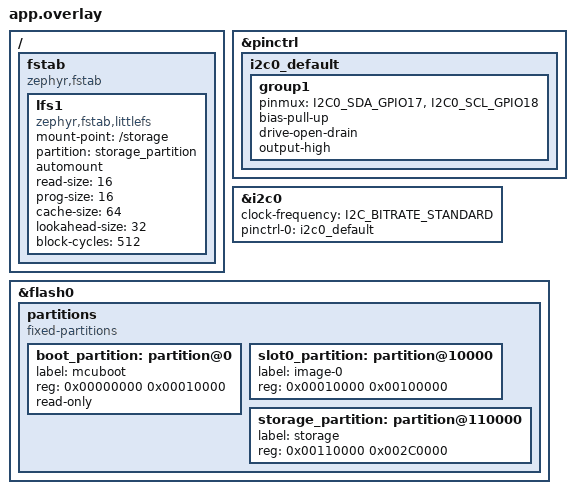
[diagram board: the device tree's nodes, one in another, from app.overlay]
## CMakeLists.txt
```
cmake_minimum_required(VERSION 3.20.0)
find_package(Zephyr REQUIRED HINTS $ENV{ZEPHYR_BASE})
project(meu_lora)

# Inclui o diretório de cabeçalhos
target_include_directories(app PRIVATE
    include
)

# # Subdiretórios
# add_subdirectory(src/federatedfearning)
# add_subdirectory(src/http)
# add_subdirectory(src/CJSON)
# add_subdirectory(src/websocket)

# add_subdirectory(src/espconfiguration)

# Adiciona os arquivos fonte do projeto
target_sources(app PRIVATE 
    src/main.c 
    # src/cJSON.c
    src/espconfiguration.c
    src/federatedlearning.c
    src/httpclient.c
    src/JSONConverter.c
    src/websocketclient.c
    src/knowledgedistillation.c
)
```

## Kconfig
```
mainmenu "Federated Learning node"

menu "Federated learning"

config FL_KNOWLEDGE_DISTILLATION
	bool "Knowledge distillation from a server-provided teacher"
	default n
	help
	  Distills a teacher model, downloaded from /api/getteachermodel at every round,
	  into the local model during training. Can also be changed at runtime with
	  KnowledgeDistillationEnable()/KnowledgeDistillationDisable().

config FL_KD_TEMPERATURE_X10
	int "Default distillation temperature x10 (30 = 3.0)"
	default 30
	range 10 200
	help
	  Used when the server does not send "distillation.temperature" with the teacher.

config FL_KD_ALPHA_PERCENT
	int "Default distillation weight alpha in percent"
	default 50
	range 0 100
	help
	  Weight of the distillation term; 0 is plain cross-entropy training.
	  Used when the server does not send "distillation.alpha" with the teacher.

endmenu

source "Kconfig.zephyr"
```

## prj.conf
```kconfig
# LORA
# CONFIG_LORA=y
# CONFIG_MAIN_STACK_SIZE=2048
# CONFIG_SYSTEM_WORKQUEUE_STACK_SIZE=2048

# LOG
CONFIG_LOG=y
CONFIG_LOG_DEFAULT_LEVEL=3

# pra usar printf
CONFIG_NEWLIB_LIBC=y
CONFIG_STDOUT_CONSOLE=y
CONFIG_PRINTK=y

# Wi-Fi Configuration
CONFIG_WIFI=y

CONFIG_WIFI_ESP32=y
CONFIG_WIFI_LOG_LEVEL_INF=y


# Network Configuration
CONFIG_NET_CONFIG_AUTO_INIT=n
CONFIG_NET_CONNECTION_MANAGER=y
CONFIG_NET_DHCPV4=y
CONFIG_NET_IF_MAX_IPV4_COUNT=2
CONFIG_NET_IPV4=y
CONFIG_NET_L2_ETHERNET=y
CONFIG_NET_L2_WIFI_MGMT=y
CONFIG_NET_MGMT=y
CONFIG_NET_MGMT_EVENT=y
CONFIG_NET_MGMT_EVENT_INFO=y
CONFIG_NET_MGMT_EVENT_QUEUE_SIZE=10
CONFIG_NET_MGMT_EVENT_STACK_SIZE=4096
CONFIG_NET_PKT_RX_COUNT=16
CONFIG_NET_PKT_TX_COUNT=16
CONFIG_NET_SOCKETS_SERVICE_STACK_SIZE=4096
CONFIG_NET_TCP=y
CONFIG_NET_UDP=y
CONFIG_NETWORKING=y

CONFIG_NET_MAX_CONN=20
CONFIG_NET_MAX_CONTEXTS=20

# LOG Configuration
CONFIG_NET_LOG=y
CONFIG_NET_DHCPV4_SERVER_LOG_LEVEL_DBG=y



# --- Rede básica ---
CONFIG_NET_IPV6=n
CONFIG_NET_SOCKETS=y


# --- Gerenciamento de rede ---
CONFIG_NET_MGMT=y
CONFIG_NET_MGMT_EVENT=y
CONFIG_NET_MGMT_EVENT_THREAD=y

# --- WebSocket & HTTP ---
CONFIG_HTTP_CLIENT=y
CONFIG_WEBSOCKET_CLIENT=y


# --- Gerenciamento de Memória e Stack ---
# Heap do kernel (k_malloc): usado pelo driver Wi-Fi (CONFIG_ESP_WIFI_HEAP_SYSTEM) e pelo kernel.
# A rede neural e o cJSON NÃO usam esse heap: usam malloc/calloc da newlib, cuja arena é a DRAM que
# sobra entre _end e _heap_sentry. Cada byte a mais aqui sai dessa arena -- com 96KB a arena caía
# para ~139KB e o nó ficava sem memória para enviar/receber o modelo depois de cachear o teacher.
CONFIG_HEAP_MEM_POOL_SIZE=65536

# Aumenta a pilha da thread principal para lidar com a recursividade do cJSON e buffers de rede
CONFIG_MAIN_STACK_SIZE=8192

# --- Sistema de Arquivos (LittleFS) ---
CONFIG_FILE_SYSTEM=y
CONFIG_FILE_SYSTEM_LITTLEFS=y
CONFIG_FLASH=y
CONFIG_FLASH_MAP=y
CONFIG_FLASH_PAGE_LAYOUT=y

# # --- Sensores e Barramentos ---
# CONFIG_I2C=y

# --- Suporte a Ponto Flutuante (Floats) nos Logs ---
CONFIG_CBPRINTF_FP_SUPPORT=y

#===aaa
# # --- Suporte a GPIO ---
# CONFIG_GPIO=y

# --- Suporte Avançado de Wi-Fi ---
CONFIG_WIFI=y
CONFIG_NET_L2_WIFI_MGMT=y
CONFIG_WIFI_LOG_LEVEL_INF=y

# Degub
# CONFIG_WIFI_LOG_LEVEL_ERR=y
# CONFIG_NET_DHCPV4_LOG_LEVEL_DBG=y
# CONFIG_NET_IPV4_LOG_LEVEL_DBG=y

CONFIG_CJSON=y

# Habilita a Biblioteca C completa com suporte a arquivos
CONFIG_NEWLIB_LIBC=y

# Liga a ponte entre o fopen() do C e o Virtual File System do Zephyr
CONFIG_POSIX_API=y
CONFIG_POSIX_FILE_SYSTEM=y

# config de flash e particionamento
CONFIG_FLASH=y
CONFIG_FLASH_MAP=y

CONFIG_FILE_SYSTEM=y
CONFIG_FILE_SYSTEM_LITTLEFS=y

# --- Knowledge distillation (teacher enviado pelo servidor em /api/getteachermodel) ---
CONFIG_FL_KNOWLEDGE_DISTILLATION=n
# Valores padrão usados se o servidor não enviar "distillation" junto com o teacher
CONFIG_FL_KD_TEMPERATURE_X10=30
CONFIG_FL_KD_ALPHA_PERCENT=50
```

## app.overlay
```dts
/* Importa o dicionário de pinos do ESP32-S3 */
#include <zephyr/dt-bindings/pinctrl/esp32s3-pinctrl.h>

/* Importa o dicionário de velocidades do I2C (Resolve o erro do BITRATE) */
#include <zephyr/dt-bindings/i2c/i2c.h>

/ {
	/* 1. Configuração de Automount do Sistema de Arquivos */
	fstab {
		compatible = "zephyr,fstab";
		lfs1: lfs1 {
			compatible = "zephyr,fstab,littlefs";
			mount-point = "/storage";
			partition = <&storage_partition>;
			automount;
			read-size = <16>;
			prog-size = <16>;
			cache-size = <64>;
			lookahead-size = <32>;
			block-cycles = <512>;
		};
	};
};

/* 2. Mapeamento dos Pinos para o ESP32-S3 (Heltec V3) */
&pinctrl {
	i2c0_default: i2c0_default {
		group1 {
			/* Pinos I2C ajustados para o hardware da Heltec V3 */
			/* Se o seu sensor estiver em pinos diferentes, mude os números abaixo (ex: GPIO41) */
			pinmux = <I2C0_SDA_GPIO17>, <I2C0_SCL_GPIO18>;
			bias-pull-up;
			drive-open-drain;
			output-high;
		};
	};
};

/* 3. Ativação do Barramento I2C */
&i2c0 {
	status = "okay";
	clock-frequency = <I2C_BITRATE_STANDARD>; 
	pinctrl-0 = <&i2c0_default>;
	pinctrl-names = "default";
};

/* 4. Redefinição das Partições da Memória Flash */
/* 4. Redefinição das Partições da Memória Flash */
&flash0 {
	/delete-node/ partitions;
	partitions {
		compatible = "fixed-partitions";
		#address-cells = <1>;
		#size-cells = <1>;

		/* CORREÇÃO: O Bootloader do ESP32-S3 inicia obrigatoriamente em 0x0 */
		boot_partition: partition@0 {
			label = "mcuboot";
			reg = <0x00000000 0x00010000>;
			read-only;
		};

		/* Partição do seu código (lógica e RTOS) */
		slot0_partition: partition@10000 {
			label = "image-0";
			reg = <0x00010000 0x00100000>; /* 1 MB para o código */
		};

		/* Partição para o dataset.csv usando LittleFS.
		 * 2.75 MB (era 2 MB): com o covertype de 17.220 linhas (326 B/linha) a maior partição de um nó chega a
		 * ~6150 linhas ~= 2.0 MB, que não cabe em 2 MB. Com o dataset HAR (32 features), uma partição Dirichlet não-IID de um nó pode
		 * passar de 1 MB sozinha (ex.: 3988 linhas ~= 1.25 MB) -- a antiga partição de 1 MB
		 * estourava o littlefs ("File system is full") em splits desbalanceados.
		 * Chip tem 4 MB no total (ver reg do &flash0); mcuboot(64K)+slot0(1M)+storage(2.75M) = ~3.8 MB,
		 * deixando margem livre no flash. */
		storage_partition: partition@110000 {
			label = "storage";
			reg = <0x00110000 0x002C0000>;
		};
	};
};
```

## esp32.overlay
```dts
/* Overlay for the generic ESP32 (classic, esp32_devkitc/esp32/procpu) boards: only the LittleFS mount and the flash
 * partitions of app.overlay (that one has the Heltec V3 / ESP32-S3 pins). Select it with DTC_OVERLAY_FILE=esp32.overlay,
 * see BOARD/OVERLAY/CHIP in run_zephyr.sh. */
/ {
	fstab {
		compatible = "zephyr,fstab";
		lfs1: lfs1 {
			compatible = "zephyr,fstab,littlefs";
			mount-point = "/storage";
			partition = <&storage_partition>;
			automount;
			read-size = <16>;
			prog-size = <16>;
			cache-size = <64>;
			lookahead-size = <32>;
			block-cycles = <512>;
		};
	};
};

/* The classic ESP32 loads its second stage from 0x1000 (the S3 from 0x0): the runner flashes zephyr.bin at the
 * boot_partition address, so it must be at 0x1000 (stock layout: partitions_0x1000_amp_4M.dtsi). Code at 0x20000,
 * then 2.75 MB of storage; everything inside the 4 MB flash of the chip. */
&flash0 {
	/delete-node/ partitions;
	partitions {
		compatible = "fixed-partitions";
		#address-cells = <1>;
		#size-cells = <1>;

		boot_partition: partition@1000 {
			label = "mcuboot";
			reg = <0x00001000 0x0000F000>;
			read-only;
		};

		sys_partition: partition@10000 {
			label = "sys";
			reg = <0x00010000 0x00010000>;
		};

		slot0_partition: partition@20000 {
			label = "image-0";
			reg = <0x00020000 0x000F0000>;
		};

		storage_partition: partition@110000 {
			label = "storage";
			reg = <0x00110000 0x002C0000>;
		};
	};
};
```

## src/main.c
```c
#include <stdio.h>

#include <zephyr/kernel.h>          // Substitui TUDO do FreeRTOS
#include <zephyr/fs/fs.h>           // Substitui o esp_spiffs.h
#include <zephyr/fs/littlefs.h>     // Sistema de arquivos recomendado para Flash
#include <zephyr/drivers/i2c.h>     // Substitui driver/i2c.h
#include <zephyr/sys/reboot.h>      // Provável substituto para funções do esp_system.h
#include <zephyr/net/net_ip.h>
#include <zephyr/storage/flash_map.h>
#include <zephyr/logging/log.h>
#include "espconfiguration.h"
#include "httpclient.h"
#include "websocketclient.h"
#include "federatedlearning.h"
#include "JSONConverter.h"
#include "knowledgedistillation.h"

LOG_MODULE_REGISTER(MAIN, LOG_LEVEL_INF);

// Defina o endereço I2C do INA219 (geralmente é 0x40)
#define INA219_ADDR 0x40

// Pinos I2C
#define SDA_PIN 21
#define SCL_PIN 22

// Define a configuração padrão do LittleFS
FS_LITTLEFS_DECLARE_DEFAULT_CONFIG(storage);

// Estrutura que mapeia a partição física para o caminho virtual
// static struct fs_mount_t lfs_storage_mnt = {
//     .type = FS_LITTLEFS,
//     .fs_data = &storage,
//     .storage_dev = (void *)FIXED_PARTITION_ID(storage_partition),
//     .mnt_point = "/storage",
// };


// // Função para montar o disco
// void mount_filesystem(void) {
//     int res = fs_mount(&lfs_storage_mnt);
//     if (res == 0) {
//         LOG_INF("LittleFS montado com sucesso em %s", lfs_storage_mnt.mnt_point);
//     } else {
//         LOG_ERR("Erro ao montar LittleFS: %d", res);
//     }
// }

void brink_error_led(int blink){

    for(int i=0;i<blink;i++){
        // gpio_set_level(LED_PIN_ERROR, 1);
        k_msleep(100);
        // gpio_set_level(LED_PIN_ERROR, 0);
    }
}

#define GLOBAL_MODEL_MAX_ATTEMPTS 5
#define SEND_MODEL_MAX_ATTEMPTS 3
// after sending, the server stops offering this round to the node; if it still does for this many polls (~4 s each)
// the model was lost in the network and is sent again, at most RESEND_MAX_PER_ROUND times per round
#define RESEND_AFTER_POLLS 2
#define RESEND_MAX_PER_ROUND 4

void node_register(){
    // gpio_set_level(LED_PIN_SYNC, 1);
    // repete até o servidor confirmar o registro (novo ou já existente)
    while (!getregisternode()) {
        printf("Registro falhou, tentando novamente...\n");
        brink_error_led(1);
        k_msleep(2000);
        wifi_wait_connected();
    }
    // gpio_set_level(LED_PIN_SYNC, 0);
}

int global_model_status(int *round){
    int status=0;
    // gpio_set_level(LED_PIN_SYNC, 1);
    status=getglobalmodelstatus(round);
    k_msleep(50);
    // gpio_set_level(LED_PIN_SYNC, 0);
    k_msleep(50);
    return status;
}

// Tentativas limitadas com backoff; retorna NULL e o loop volta a checar o status
FederatedLearning *global_model(){
    for (int attempt = 1; attempt <= GLOBAL_MODEL_MAX_ATTEMPTS; attempt++) {
        // gpio_set_level(LED_PIN_SYNC, 1);
        FederatedLearning *globalmodelinstance = getglobalmodel();
        // gpio_set_level(LED_PIN_SYNC, 0);
        if (globalmodelinstance != NULL) {
            printf("Json not null\n");
            return globalmodelinstance;
        }
        printf("Json null (tentativa %d)\n", attempt);
        brink_error_led(2);
        k_msleep(1000 * attempt);
    }
    return NULL;
}

// Envia o modelo já treinado, sem retreinar, até SEND_MODEL_MAX_ATTEMPTS vezes
int send_local_model(int round){
    for (int attempt = 1; attempt <= SEND_MODEL_MAX_ATTEMPTS; attempt++) {
        if (websocket_send_local_model(round) == 0) {
            return 0;
        }
        printf("Envio do modelo falhou (tentativa %d)\n", attempt);
        k_msleep(1000 * attempt);
        wifi_wait_connected();
    }
    return -1;
}

void deep_learning(){

    // rodada do último modelo global treinado e enviado; evita treinar 2x a mesma rodada
    int last_trained_round = -1;
    int stale_polls = 0, resends = 0;

    while (1){
        wifi_wait_connected();

        int round = -1;
        if(!global_model_status(&round)){
            k_msleep(4000);
            continue;
        }

        if (round == last_trained_round) {
            // the server still offers the round whose model was already sent: it did not register it
            // (a "sent" model can be lost in the network); send the same trained model again
            stale_polls++;
            if (stale_polls >= RESEND_AFTER_POLLS && resends < RESEND_MAX_PER_ROUND) {
                resends++;
                stale_polls = 0;
                printf("Servidor ainda aguarda o modelo da rodada %d, reenviando (%d/%d)\n", round, resends, RESEND_MAX_PER_ROUND);
                send_local_model(round);
            }
            k_msleep(4000);
            continue;
        }
        stale_polls = 0;
        resends = 0;

        FederatedLearning *globalmodelinstance = global_model();
        if (globalmodelinstance == NULL) {
            continue;
        }

        replaceNeuralNetwork(globalmodelinstance);

        // o teacher é imutável após a fase 1: busca só uma vez e mantém em cache nas rodadas seguintes
        if (KnowledgeDistillationIsEnabled() && KnowledgeDistillationGetTeacher() == NULL) {
            if (getteachermodel() == TEACHER_FETCH_NETWORK_ERROR) {
                // do not train this round without distillation because of a network error: try again
                printf("Teacher nao baixado (erro de rede): rodada %d adiada\n", round);
                k_msleep(4000);
                continue;
            }
        }

        NeuralNetworkTraining();

        if (getFederatedLearningInstance()->trainingscounter <= 0) {
            printf("Nada foi treinado, modelo não enviado\n");
            brink_error_led(3);
            k_msleep(4000);
            continue;
        }

        if (send_local_model(round) == 0) {
            last_trained_round = round;
        }
    }
}


void deep_learning_test(){
    int round = -1;
    if(global_model_status(&round)){
        FederatedLearning *globalmodelinstance = getglobalmodel();
        if (globalmodelinstance == NULL) {
            return;
        }
        printf("getmodel\n");
        // replaceNeuralNetwork assume a posse do modelo recebido
        replaceNeuralNetwork(globalmodelinstance);
        FederatedLearning *FDI = getFederatedLearningInstance();
        PrintNeuralNetwork(FDI->neuralnetwork);
        if (KnowledgeDistillationIsEnabled() && KnowledgeDistillationGetTeacher() == NULL) {
            getteachermodel();
        }
        NeuralNetworkTraining();
        PrintNeuralNetwork(FDI->neuralnetwork);
    }
}


void start_esp32_configuration(){

    // UARTConfiguration();
    GPIOConfiguration();
    WIFIConfiguration();
    // SPIFFSConfiguration();
    
    // gpio_set_level(LED_PIN_ERROR, 0);
    // gpio_set_level(LED_PIN_SYNC, 0);
    k_msleep(2000);

}

void start_federated_learning_system_button(){
    //int startled = 0;
    /*while (gpio_get_level(BUTTON_PIN)){
        startled = ~startled;
        gpio_set_level(LED_PIN_WORKING, startled);
        k_msleep(250);
    }*/
    //gpio_set_level(LED_PIN_WORKING, 1);
}


int main(){
    printf("iniciou");
    start_esp32_configuration();
    // mount_filesystem();
    printf("1");
    start_federated_learning_system_button();

    // Não segue sem IP: espera (com novas tentativas de conexão) até o roteador fornecer o endereço
    wifi_wait_connected();
    printf("Acesso liberado! Iniciando comunicacao com o servidor...\n");
    
    printf("enter noderegister\n");
    node_register();
    printf("pass noderegister\n");
    deep_learning();

    return 0;
}
```

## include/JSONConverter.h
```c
#ifndef _jsonconverter
#define _jsonconverter

#include "federatedlearning.h"
#include <cJSON.h>

cJSON* federatedLearningToJSON(const FederatedLearning* federatedLearning);
FederatedLearning* JSONToFederatedLearning(const cJSON* json);
// the "flat" network of GET /api/getteachermodelflat (weights and biases as comma separated strings)
FederatedLearning* JSONFlatToFederatedLearning(const cJSON* json);
// the model as one flat JSON text, written without a cJSON tree (the node's upload); round < 0 and type NULL are
// left out. malloc'ed, free() it; NULL when there is no memory or the network is not fully connected
char* federatedLearningToFlatString(const FederatedLearning* federatedLearning, int round, const char* type);

#endif
```

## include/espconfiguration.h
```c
#ifndef _espconfiguration
#define _espconfiguration

/* * Todas as bibliotecas esp_* e driver/* foram removidas.
 * O Zephyr cuidará das dependências dentro dos arquivos .c
 */

// Pinos
#define LED_PIN_ERROR 12
#define LED_PIN_WORKING 14
#define LED_PIN_SYNC 27
#define BUTTON_PIN 26

#include <stdbool.h>

extern struct k_sem wifi_connected_sem;

// Credenciais de Rede
#define WIFI_SSID       "flnet"
#define WIFI_PASSWORD   "senha12345"

// Configs http
#define SERVER_IP "10.42.0.1"
#define SERVER_PORT 8888


// Configs para o Websocket
#define WS_SERVER_IP "10.42.0.1"
#define WS_SERVER_PORT 8080
#define WS_SERVER_PATH "/"

// Training
#define DATA_PATH "/storage/dataset.csv"

//buffer de leitura dados
#define READ_BUFFER_SIZE 1024

// Funções de inicialização restantes
void WIFIConfiguration(void);
void GPIOConfiguration(void);
bool wifi_is_connected(void);
void wifi_wait_connected(void);

#endif
```

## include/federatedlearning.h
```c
#ifndef _federatedlearning
#define _federatedlearning

//activation function
#define PERCEPTRON 1
#define RELU 2
#define SIGMOID 3

//output activation function
#define SOFTMAX 4

//identity activation, used for the autoencoder teacher's reconstruction layer
#define LINEAR 5

//loss function
#define MINIMAL_MEAN_SQUARE 1
#define CATEGORICAL_CROSS_ENTROPY 2

//regularization
#define NONE_REGULARIZATION 0
#define L1 1
#define L2 2

typedef struct Weight {
  float weight;
  struct Weight * previousweight, * nextweight;
}Weight;

typedef struct Neuron {
  char neurontype[20];
  int weights;
  float activationfunctionvalue;
  float preactivation; // Z before the activation (logit on the output layer), not serialized
  float bias;
  struct Weight * firstweight, * lastweight;
  struct Neuron * nextneuron, * previousneuron;
}Neuron;

typedef struct Layer {
  int activationfunctiontype;
  int neurons;
  struct Neuron * firstneuron, * lastneuron;
  struct Layer * previouslayer, * nextlayer;
}Layer;

typedef struct LayerConfig{
  struct LayerConfig *first, *next;
  int neurons;
  int activationfunctiontype;
}LayerConfig;

typedef struct NeuralNetwork {
  int epoch;
  float alpha;
  int regularization;
  float lambda;
  int percentualtraining;
  int lossfunctiontype;
  int layers;
  struct Layer * firstlayer, * lastlayer;
}NeuralNetwork;

typedef struct FederatedLearning{
    int globalmodelstatus;
    int trainingscounter;
    NeuralNetwork *neuralnetwork;
}FederatedLearning;

FederatedLearning *getFederatedLearningInstance();
void replaceNeuralNetwork(FederatedLearning * newfederatedlearninginstance);
void freeNeuralNetwork(NeuralNetwork *neuralnetwork);
void freeFederatedLearning(FederatedLearning *federatedlearning);
void mergeNeuralNetwork(FederatedLearning * newfederatedlearninginstance);
void PrintNeuralNetwork(NeuralNetwork * neuralnetwork);
//void NeuralNetworkTraining(NeuralNetwork * neuralnetwork, float LearningRate,int epoch,int PercentualTraining);
void NeuralNetworkTraining();
void FeedFoward(NeuralNetwork * neuralnetwork);
float ActivationFunctionCalculaton(float Z, int activationfunctiontype);
float ActivationFunctionDerivativeCalculation(float a, int activationfunctiontype);
void BackPropagation(NeuralNetwork *neuralnetwork, const float *outputdelta, float alpha, int regularization, float lambda, const float *hintdelta, int hintlayerindex);
void CrossEntropyOutputDelta(NeuralNetwork *neuralnetwork, const float *label, float *delta);
void ReconstructionOutputDelta(NeuralNetwork *neuralnetwork, const float *label, float *delta);
float RidgeRegressionCalculation(NeuralNetwork *neuralnetwork,float lambda);
float LassoRegressionCalculation(NeuralNetwork *neuralnetwork,float lambda);
float LossFunctionCalculation(NeuralNetwork * neuralnetwork, float *labelvector, int regularization,float lambda);
void teste();

int contar_instancias(const char *caminho_arquivo);

#endif
```

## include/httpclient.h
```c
#ifndef _httpclient
#define _httpclient

#include <zephyr/net/http/client.h>
#include <zephyr/net/socket.h> 

#include "espconfiguration.h"
#include "federatedlearning.h"
#include "JSONConverter.h"

#define MAX_RETRIES 3
#define TIMEOUT_MS 5000

// 2. Isolamos as Rotas (Paths) para o Cabeçalho HTTP
#define GET_GLOBAL_MODEL        "/api/getglobalmodel"
#define GET_GLOBAL_MODEL_FLAT   "/api/getglobalmodelflat"
#define GET_GLOBAL_MODEL_STATUS "/api/checkglobalmodel"
#define GET_REGISTER_NODE       "/api/noderegister"
#define POST_GLOBAL_MODEL       "/api/postglobalmodel"
#define GET_TEACHER_MODEL       "/api/getteachermodel"
#define GET_TEACHER_MODEL_FLAT  "/api/getteachermodelflat"

// 3. Assinaturas das funções (removendo os parâmetros do FreeRTOS)
FederatedLearning* getglobalmodel(void);
int getglobalmodelstatus(int *round);
void postglobalmodel(void);
int getregisternode(void);
// getteachermodel(): 0 = teacher installed, -1 = unavailable/invalid (train without KD), TEACHER_FETCH_NETWORK_ERROR = try again
#define TEACHER_FETCH_NETWORK_ERROR (-3)
int getteachermodel(void);
// 1 once the flat model endpoints worked: the node may then upload its model in the flat form
int server_supports_flat(void);

// Alterado para void (sem o pvParameters do FreeRTOS)
void http_post_task(void);

#endif
```

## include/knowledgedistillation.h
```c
#ifndef _knowledgedistillation
#define _knowledgedistillation

#include <stdbool.h>
#include "federatedlearning.h"

/*
 * Knowledge distillation (KD) from a teacher model sent by the server. Two modes:
 *
 * KD_MODE_LOGIT (classifier teacher, output-level distillation):
 *   Loss per sample (z_s: student logits, z_t: teacher logits, T: temperature, alpha: distillation weight):
 *     L = (1 - alpha) * CE(y, softmax(z_s)) + alpha * T^2 * KL(softmax(z_t / T) || softmax(z_s / T))
 *   Gradient w.r.t. the student logits:
 *     dL/dz_s_i = (1 - alpha) * (p_i - y_i) + alpha * T * (q_s_i - q_t_i)
 *   The teacher needs the same number of inputs/outputs as the student and a SOFTMAX output layer.
 *
 * KD_MODE_LATENT (autoencoder teacher, latent/hidden-layer distillation):
 *   Loss per sample (h_s: student's last hidden layer, h_t: teacher's latent layer, both post-activation,
 *   same width n):
 *     L = (1 - alpha) * CE(y, softmax(z_s)) + alpha * MSE(h_s, h_t)
 *   KnowledgeDistillationFeatureDelta gives dMSE/d(h_s_i), i.e. w.r.t. the hint layer's POST-activation
 *   value. The caller must multiply it by alpha AND by the hint layer's own activation derivative
 *   (ActivationFunctionDerivativeCalculation) to get dLoss/d(preactivation) before adding it, as hintdelta,
 *   to what BackPropagation already computes there from the (1 - alpha)-scaled output-layer delta:
 *     hintdelta_i = alpha * (2/n) * (h_s_i - h_t_i) * f'(Z_i)
 *   temperature is accepted but unused in this mode. The teacher needs the same number of inputs as the
 *   student. The server only ever serves Encoder+Latent for this mode (Decoder/Reconstruction are never
 *   read here), so the teacher's latent layer is always its lastlayer -- same convention KD_MODE_LOGIT
 *   already uses for the output layer. The student's hint layer is the hidden layer at studentlayerindex
 *   (0-based, sent by the server; -1 = last hidden layer) and must have the same width as that latent layer.
 *
 * All functions must be called from the same thread that runs the training.
 */

#define KD_MODE_LOGIT 0
#define KD_MODE_LATENT 1

typedef struct KnowledgeDistillationConfig {
  bool enabled;
  int mode;             // KD_MODE_LOGIT or KD_MODE_LATENT (from the teacher once one is set)
  float temperature;    // KD_MODE_LOGIT only
  float alpha;
  int studentlayerindex; // KD_MODE_LATENT only; 0-based student hint layer, -1 = last hidden layer
} KnowledgeDistillationConfig;

// runtime activation; the defaults come from CONFIG_FL_KNOWLEDGE_DISTILLATION, CONFIG_FL_KD_TEMPERATURE_X10
// and CONFIG_FL_KD_ALPHA_PERCENT. mode is only ever known once a teacher is received.
int KnowledgeDistillationEnable(float temperature, float alpha);
void KnowledgeDistillationDisable(void);
bool KnowledgeDistillationIsEnabled(void);

// effective configuration: the values sent with the teacher override the local ones
KnowledgeDistillationConfig KnowledgeDistillationGetConfig(void);

// takes ownership of teacher (also on error). mode: KD_MODE_LOGIT or KD_MODE_LATENT.
// temperature/alpha <= 0 or out of range keep the local defaults (KD_MODE_LOGIT only; ignored for LATENT).
// studentlayerindex: KD_MODE_LATENT hint layer (-1 = last hidden layer); checked against the student later.
int KnowledgeDistillationSetTeacher(FederatedLearning *teacher, int mode, float temperature, float alpha,
                                    int studentlayerindex);
NeuralNetwork *KnowledgeDistillationGetTeacher(void);
void KnowledgeDistillationClearTeacher(void);

// checks the current teacher against student per the active mode (see the comment above)
bool KnowledgeDistillationTeacherCompatible(const NeuralNetwork *student);

// KD_MODE_LATENT: 0-based index of the student's hint layer, or -1 if it is not a hidden layer of student
int KnowledgeDistillationStudentHintIndex(const NeuralNetwork *student);

// KD_MODE_LOGIT math (output logits, temperature-scaled softmax + KL)
float KnowledgeDistillationLoss(const float *label, const float *studentlogits, const float *teacherlogits,
                                int n, float temperature, float alpha);
void KnowledgeDistillationOutputDelta(const float *label, const float *studentlogits, const float *teacherlogits,
                                      int n, float temperature, float alpha, float *delta);

// KD_MODE_LATENT math (hidden-layer feature matching, mean squared error)
float KnowledgeDistillationFeatureLoss(const float *studenthidden, const float *teacherhidden, int n);
void KnowledgeDistillationFeatureDelta(const float *studenthidden, const float *teacherhidden, int n, float *delta);

#endif
```

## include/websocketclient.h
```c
#ifndef _websocketclient
#define _websocketclient

#include "espconfiguration.h"

int websocket_send_local_model(int round);

#endif
```

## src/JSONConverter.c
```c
#include "JSONConverter.h"
#include <string.h>
#include <stdio.h>
#include <stdlib.h>
#include <stdarg.h>

//JSON TO FFEDERATED LEARNING  
cJSON* federatedLearningToJSON(const FederatedLearning* federatedLearning) {
    cJSON* root = cJSON_CreateObject();

    cJSON_AddItemToObject(root, "globalmodelstatus", cJSON_CreateNumber(federatedLearning->globalmodelstatus));
    cJSON_AddItemToObject(root, "trainingscounter", cJSON_CreateNumber(federatedLearning->trainingscounter));
    
    cJSON* jsonNeuralNetwork = cJSON_CreateObject();
    cJSON_AddItemToObject(root, "neuralnetwork", jsonNeuralNetwork);

    cJSON_AddItemToObject(jsonNeuralNetwork, "epoch", cJSON_CreateNumber(federatedLearning->neuralnetwork->epoch));
    cJSON_AddItemToObject(jsonNeuralNetwork, "alpha", cJSON_CreateNumber(federatedLearning->neuralnetwork->alpha));
    cJSON_AddItemToObject(jsonNeuralNetwork, "regularization", cJSON_CreateNumber(federatedLearning->neuralnetwork->regularization));
    cJSON_AddItemToObject(jsonNeuralNetwork, "lambda", cJSON_CreateNumber(federatedLearning->neuralnetwork->lambda));
    cJSON_AddItemToObject(jsonNeuralNetwork, "percentualtraining", cJSON_CreateNumber(federatedLearning->neuralnetwork->percentualtraining));
    cJSON_AddItemToObject(jsonNeuralNetwork, "lossfunctiontype", cJSON_CreateNumber(federatedLearning->neuralnetwork->lossfunctiontype));
    cJSON_AddItemToObject(jsonNeuralNetwork, "layers", cJSON_CreateNumber(federatedLearning->neuralnetwork->layers));

    cJSON* layersArray = cJSON_CreateArray();
    struct Layer* currentLayer = federatedLearning->neuralnetwork->firstlayer;

    while (currentLayer != NULL) {
        cJSON* layerObject = cJSON_CreateObject();
        cJSON_AddItemToObject(layerObject, "activationfunctiontype", cJSON_CreateNumber(currentLayer->activationfunctiontype));
        cJSON_AddItemToObject(layerObject, "neurons", cJSON_CreateNumber(currentLayer->neurons));

        cJSON* neuronsArray = cJSON_CreateArray();
        struct Neuron* currentNeuron = currentLayer->firstneuron;

        while (currentNeuron != NULL) {
            cJSON* neuronObject = cJSON_CreateObject();
            cJSON_AddItemToObject(neuronObject, "neurontype", cJSON_CreateString(currentNeuron->neurontype));
            cJSON_AddItemToObject(neuronObject, "weights", cJSON_CreateNumber(currentNeuron->weights));
            cJSON_AddItemToObject(neuronObject, "bias", cJSON_CreateNumber(currentNeuron->bias));

            cJSON* weightsArray = cJSON_CreateArray();
            struct Weight* currentWeight = currentNeuron->firstweight;

            while (currentWeight != NULL) {
                cJSON_AddItemToArray(weightsArray, cJSON_CreateNumber(currentWeight->weight));
                currentWeight = currentWeight->nextweight;
            }

            cJSON_AddItemToObject(neuronObject, "weightsArray", weightsArray);

            cJSON_AddItemToArray(neuronsArray, neuronObject);
            currentNeuron = currentNeuron->nextneuron;
        }

        cJSON_AddItemToObject(layerObject, "neuronsArray", neuronsArray);
        cJSON_AddItemToArray(layersArray, layerObject);
        currentLayer = currentLayer->nextlayer;
    }

    cJSON_AddItemToObject(jsonNeuralNetwork, "layersArray", layersArray);



    return root;
}

//JSON TO FEDERATED LEARNING

static int GetInt(const cJSON* object, const char* name, int* value) {
    cJSON* item = cJSON_GetObjectItem(object, name);
    if (!cJSON_IsNumber(item)) {
        return 0;
    }
    *value = item->valueint;
    return 1;
}

static int GetFloat(const cJSON* object, const char* name, float* value) {
    cJSON* item = cJSON_GetObjectItem(object, name);
    if (!cJSON_IsNumber(item)) {
        return 0;
    }
    *value = (float)item->valuedouble;
    return 1;
}

static Neuron* JSONToNeuron(const cJSON* neuronElement) {

    Neuron* neuron = (Neuron*)calloc(1, sizeof(Neuron));
    if (neuron == NULL) {
        return NULL;
    }

    cJSON* neurontypeItem = cJSON_GetObjectItem(neuronElement, "neurontype");
    cJSON* weightsArrayItem = cJSON_GetObjectItem(neuronElement, "weightsArray");

    if (!cJSON_IsString(neurontypeItem) ||
        !GetInt(neuronElement, "weights", &neuron->weights) ||
        !GetFloat(neuronElement, "bias", &neuron->bias) ||
        !cJSON_IsArray(weightsArrayItem)) {
        free(neuron);
        return NULL;
    }

    strncpy(neuron->neurontype, neurontypeItem->valuestring, sizeof(neuron->neurontype) - 1);
    neuron->neurontype[sizeof(neuron->neurontype) - 1] = '\0';

    int k = 0;
    cJSON* weightElement;
    cJSON_ArrayForEach(weightElement, weightsArrayItem) {

        Weight* weight = (Weight*)calloc(1, sizeof(Weight));
        if (weight == NULL || !cJSON_IsNumber(weightElement)) {
            free(weight);
            k = -1;
            break;
        }

        weight->weight = (float)weightElement->valuedouble;

        if (neuron->lastweight == NULL) {
            neuron->firstweight = neuron->lastweight = weight;
        } else {
            neuron->lastweight->nextweight = weight;
            weight->previousweight = neuron->lastweight;
            neuron->lastweight = weight;
        }
        k++;
    }

    //the weights counter must match the weights list
    if (k != neuron->weights) {
        Weight* currentweight = neuron->firstweight;
        while (currentweight != NULL) {
            Weight* nextweight = currentweight->nextweight;
            free(currentweight);
            currentweight = nextweight;
        }
        free(neuron);
        return NULL;
    }

    return neuron;
}

static int JSONToLayers(const cJSON* layersArrayItem, NeuralNetwork* neuralnetwork) {

    int i = 0;
    cJSON* layerElement;
    cJSON_ArrayForEach(layerElement, layersArrayItem) {

        Layer* layer = (Layer*)calloc(1, sizeof(Layer));
        if (layer == NULL) {
            return 0;
        }

        //link first so freeNeuralNetwork releases it on error
        if (neuralnetwork->lastlayer == NULL) {
            neuralnetwork->firstlayer = neuralnetwork->lastlayer = layer;
        } else {
            neuralnetwork->lastlayer->nextlayer = layer;
            layer->previouslayer = neuralnetwork->lastlayer;
            neuralnetwork->lastlayer = layer;
        }
        i++;

        cJSON* neuronsArrayItem = cJSON_GetObjectItem(layerElement, "neuronsArray");
        if (!GetInt(layerElement, "neurons", &layer->neurons) ||
            !GetInt(layerElement, "activationfunctiontype", &layer->activationfunctiontype) ||
            !cJSON_IsArray(neuronsArrayItem)) {
            return 0;
        }

        int j = 0;
        cJSON* neuronElement;
        cJSON_ArrayForEach(neuronElement, neuronsArrayItem) {

            Neuron* neuron = JSONToNeuron(neuronElement);
            if (neuron == NULL) {
                return 0;
            }

            if (layer->lastneuron == NULL) {
                layer->firstneuron = layer->lastneuron = neuron;
            } else {
                layer->lastneuron->nextneuron = neuron;
                neuron->previousneuron = layer->lastneuron;
                layer->lastneuron = neuron;
            }
            j++;
        }

        if (j != layer->neurons || j == 0) {
            return 0;
        }
    }

    return i == neuralnetwork->layers;
}

FederatedLearning* JSONToFederatedLearning(const cJSON* json) {
    if (json == NULL || !cJSON_IsObject(json)) {
        printf("Não foi possível converter.\n");
        return NULL;
    }

    FederatedLearning* federatedLearning = (FederatedLearning*)calloc(1, sizeof(FederatedLearning));
    if (federatedLearning == NULL) {
        return NULL;  // Falha na alocação de memória
    }

    GetInt(json, "globalmodelstatus", &federatedLearning->globalmodelstatus);
    GetInt(json, "trainingscounter", &federatedLearning->trainingscounter);

    cJSON* neuralNetworkItem = cJSON_GetObjectItem(json, "neuralnetwork");
    if (!cJSON_IsObject(neuralNetworkItem)) {
        printf("JSON sem o campo neuralnetwork.\n");
        freeFederatedLearning(federatedLearning);
        return NULL;
    }

    NeuralNetwork* neuralnetwork = (NeuralNetwork*)calloc(1, sizeof(NeuralNetwork));
    if (neuralnetwork == NULL) {
        freeFederatedLearning(federatedLearning);
        return NULL;
    }
    federatedLearning->neuralnetwork = neuralnetwork;

    GetInt(neuralNetworkItem, "epoch", &neuralnetwork->epoch);
    GetFloat(neuralNetworkItem, "alpha", &neuralnetwork->alpha);
    GetInt(neuralNetworkItem, "regularization", &neuralnetwork->regularization);
    GetFloat(neuralNetworkItem, "lambda", &neuralnetwork->lambda);
    GetInt(neuralNetworkItem, "percentualtraining", &neuralnetwork->percentualtraining);
    GetInt(neuralNetworkItem, "lossfunctiontype", &neuralnetwork->lossfunctiontype);

    cJSON* layersArrayItem = cJSON_GetObjectItem(neuralNetworkItem, "layersArray");

    if (!GetInt(neuralNetworkItem, "layers", &neuralnetwork->layers) ||
        neuralnetwork->layers < 2 ||
        !cJSON_IsArray(layersArrayItem) ||
        !JSONToLayers(layersArrayItem, neuralnetwork)) {
        printf("Estrutura da rede neural inválida no JSON.\n");
        freeFederatedLearning(federatedLearning);
        return NULL;
    }

    return federatedLearning;
}

//FLAT FORM OF THE NETWORK (see NeuralNetworkToFlatJSON in the server)
//the weights and biases arrive as comma separated strings; they are read with strtof straight into the Weight
//lists, so no cJSON node is created per number (that was ~76 B/weight, more than a board with 80 KB of heap has)

//reads the next float of the list and moves the cursor past the comma; 0 when there is none
static int NextFloat(const char** cursor, float* value) {
    char* end = NULL;
    float v = strtof(*cursor, &end);
    if (end == *cursor) {
        return 0;
    }
    *value = v;
    *cursor = (*end == ',') ? end + 1 : end;
    return 1;
}

//the integers of a JSON array into out[count]; 0 when the array does not have exactly count numbers
static int GetIntArray(const cJSON* object, const char* name, int* out, int count) {
    cJSON* array = cJSON_GetObjectItem(object, name);
    if (!cJSON_IsArray(array) || cJSON_GetArraySize(array) != count) {
        return 0;
    }
    int i = 0;
    cJSON* element;
    cJSON_ArrayForEach(element, array) {
        if (!cJSON_IsNumber(element)) {
            return 0;
        }
        out[i++] = element->valueint;
    }
    return 1;
}

static int FlatToLayers(const cJSON* networkItem, NeuralNetwork* neuralnetwork) {
    int layers = neuralnetwork->layers;
    int* neurons = (int*)malloc(2 * layers * sizeof(int));
    if (neurons == NULL) {
        return 0;
    }
    int* activations = neurons + layers;

    cJSON* weightsItem = cJSON_GetObjectItem(networkItem, "weights");
    cJSON* biasesItem = cJSON_GetObjectItem(networkItem, "biases");
    if (!GetIntArray(networkItem, "neurons", neurons, layers) ||
        !GetIntArray(networkItem, "activations", activations, layers) ||
        !cJSON_IsString(weightsItem) || !cJSON_IsString(biasesItem)) {
        free(neurons);
        return 0;
    }

    const char* weightscursor = weightsItem->valuestring;
    const char* biasescursor = biasesItem->valuestring;
    int ok = 1;

    for (int i = 0; i < layers && ok; i++) {
        Layer* layer = (Layer*)calloc(1, sizeof(Layer));
        if (layer == NULL) {
            ok = 0;
            break;
        }
        //link first so freeNeuralNetwork releases it on error
        if (neuralnetwork->lastlayer == NULL) {
            neuralnetwork->firstlayer = neuralnetwork->lastlayer = layer;
        } else {
            neuralnetwork->lastlayer->nextlayer = layer;
            layer->previouslayer = neuralnetwork->lastlayer;
            neuralnetwork->lastlayer = layer;
        }
        layer->neurons = neurons[i];
        layer->activationfunctiontype = activations[i];
        if (layer->neurons <= 0) {
            ok = 0;
            break;
        }

        //fully connected: as many weights as neurons in the previous layer (none in the input layer)
        int weightsperneuron = (i == 0) ? 0 : neurons[i - 1];
        const char* type = (i == 0) ? "INPUT" : (i == layers - 1) ? "OUTPUT" : "HIDDEN";

        for (int j = 0; j < layer->neurons && ok; j++) {
            Neuron* neuron = (Neuron*)calloc(1, sizeof(Neuron));
            if (neuron == NULL) {
                ok = 0;
                break;
            }
            if (layer->lastneuron == NULL) {
                layer->firstneuron = layer->lastneuron = neuron;
            } else {
                layer->lastneuron->nextneuron = neuron;
                neuron->previousneuron = layer->lastneuron;
                layer->lastneuron = neuron;
            }
            strncpy(neuron->neurontype, type, sizeof(neuron->neurontype) - 1);
            neuron->weights = weightsperneuron;
            if (!NextFloat(&biasescursor, &neuron->bias)) {
                ok = 0;
                break;
            }
            for (int k = 0; k < weightsperneuron; k++) {
                Weight* weight = (Weight*)calloc(1, sizeof(Weight));
                if (weight == NULL) {
                    ok = 0;
                    break;
                }
                if (neuron->lastweight == NULL) {
                    neuron->firstweight = neuron->lastweight = weight;
                } else {
                    neuron->lastweight->nextweight = weight;
                    weight->previousweight = neuron->lastweight;
                    neuron->lastweight = weight;
                }
                if (!NextFloat(&weightscursor, &weight->weight)) {
                    ok = 0;
                    break;
                }
            }
        }
    }
    free(neurons);

    //both lists must be used up exactly: a shorter or longer list means the sender and this node disagree
    while (*weightscursor == ' ') weightscursor++;
    while (*biasescursor == ' ') biasescursor++;
    return ok && *weightscursor == '\0' && *biasescursor == '\0';
}

FederatedLearning* JSONFlatToFederatedLearning(const cJSON* json) {
    if (json == NULL || !cJSON_IsObject(json)) {
        printf("Não foi possível converter.\n");
        return NULL;
    }

    FederatedLearning* federatedLearning = (FederatedLearning*)calloc(1, sizeof(FederatedLearning));
    if (federatedLearning == NULL) {
        return NULL;
    }

    GetInt(json, "globalmodelstatus", &federatedLearning->globalmodelstatus);
    GetInt(json, "trainingscounter", &federatedLearning->trainingscounter);

    cJSON* networkItem = cJSON_GetObjectItem(json, "neuralnetwork");
    if (!cJSON_IsObject(networkItem)) {
        printf("JSON sem o campo neuralnetwork.\n");
        freeFederatedLearning(federatedLearning);
        return NULL;
    }

    NeuralNetwork* neuralnetwork = (NeuralNetwork*)calloc(1, sizeof(NeuralNetwork));
    if (neuralnetwork == NULL) {
        freeFederatedLearning(federatedLearning);
        return NULL;
    }
    federatedLearning->neuralnetwork = neuralnetwork;

    GetInt(networkItem, "epoch", &neuralnetwork->epoch);
    GetFloat(networkItem, "alpha", &neuralnetwork->alpha);
    GetInt(networkItem, "regularization", &neuralnetwork->regularization);
    GetFloat(networkItem, "lambda", &neuralnetwork->lambda);
    GetInt(networkItem, "percentualtraining", &neuralnetwork->percentualtraining);
    GetInt(networkItem, "lossfunctiontype", &neuralnetwork->lossfunctiontype);

    if (!GetInt(networkItem, "layers", &neuralnetwork->layers) || neuralnetwork->layers < 2 || neuralnetwork->layers > 64 ||
        !FlatToLayers(networkItem, neuralnetwork)) {
        printf("Estrutura da rede neural inválida no JSON plano.\n");
        freeFederatedLearning(federatedLearning);
        return NULL;
    }

    return federatedLearning;
}

//THE MODEL AS ONE FLAT JSON TEXT (the node's upload, see NeuralNetworkToFlatJSON in the server for the format)
//written straight into one buffer: the cJSON tree of the same model is ~76 B per weight, more than a board with
//80 KB of heap can hold next to the teacher; here 260 weights take ~5 KB
static int FlatAppend(char* buf, size_t cap, size_t* len, const char* fmt, ...) {
    va_list args;
    va_start(args, fmt);
    int n = vsnprintf(buf + *len, cap - *len, fmt, args);
    va_end(args);
    if (n < 0 || (size_t)n >= cap - *len) {
        return 0;
    }
    *len += (size_t)n;
    return 1;
}

char* federatedLearningToFlatString(const FederatedLearning* federatedLearning, int round, const char* type) {
    if (federatedLearning == NULL || federatedLearning->neuralnetwork == NULL) {
        return NULL;
    }
    const NeuralNetwork* network = federatedLearning->neuralnetwork;

    size_t weightscount = 0, biasescount = 0;
    int layers = 0;
    for (const Layer* l = network->firstlayer; l != NULL; l = l->nextlayer) {
        layers++;
        for (const Neuron* n = l->firstneuron; n != NULL; n = n->nextneuron) {
            biasescount++;
            const Weight* w = n->firstweight;
            for (int k = 0; k < n->weights; k++, w = w->nextweight) {
                if (w == NULL) {
                    return NULL;
                }
                weightscount++;
            }
            //fully connected: as many weights as neurons in the previous layer
            if (n->weights != (l->previouslayer != NULL ? l->previouslayer->neurons : 0)) {
                return NULL;
            }
        }
    }
    if (layers != network->layers) {
        return NULL;
    }

    // header + per layer entries + 16 bytes per number ("-1.23456789e-05," is the longest)
    size_t cap = 640 + (type != NULL ? strlen(type) : 0) + (size_t)layers * 24 + (weightscount + biasescount) * 16;
    char* buf = (char*)malloc(cap);
    if (buf == NULL) {
        return NULL;
    }
    size_t len = 0;
    int ok = FlatAppend(buf, cap, &len, "{\"format\":\"flat\",\"globalmodelstatus\":%d,\"trainingscounter\":%d",
                        federatedLearning->globalmodelstatus, federatedLearning->trainingscounter);
    if (round >= 0) {
        ok = ok && FlatAppend(buf, cap, &len, ",\"round\":%d", round);
    }
    if (type != NULL) {
        ok = ok && FlatAppend(buf, cap, &len, ",\"type\":\"%s\"", type);
    }
    ok = ok && FlatAppend(buf, cap, &len,
                          ",\"neuralnetwork\":{\"epoch\":%d,\"alpha\":%.9g,\"regularization\":%d,\"lambda\":%.9g,"
                          "\"percentualtraining\":%d,\"lossfunctiontype\":%d,\"layers\":%d,\"neurons\":[",
                          network->epoch, (double)network->alpha, network->regularization, (double)network->lambda,
                          network->percentualtraining, network->lossfunctiontype, network->layers);
    for (const Layer* l = network->firstlayer; l != NULL && ok; l = l->nextlayer) {
        ok = FlatAppend(buf, cap, &len, l == network->firstlayer ? "%d" : ",%d", l->neurons);
    }
    ok = ok && FlatAppend(buf, cap, &len, "],\"activations\":[");
    for (const Layer* l = network->firstlayer; l != NULL && ok; l = l->nextlayer) {
        ok = FlatAppend(buf, cap, &len, l == network->firstlayer ? "%d" : ",%d", l->activationfunctiontype);
    }
    ok = ok && FlatAppend(buf, cap, &len, "],\"weights\":\"");
    int first = 1;
    for (const Layer* l = network->firstlayer; l != NULL && ok; l = l->nextlayer) {
        for (const Neuron* n = l->firstneuron; n != NULL && ok; n = n->nextneuron) {
            for (const Weight* w = n->firstweight; w != NULL && ok; w = w->nextweight) {
                ok = FlatAppend(buf, cap, &len, first ? "%.9g" : ",%.9g", (double)w->weight);
                first = 0;
            }
        }
    }
    ok = ok && FlatAppend(buf, cap, &len, "\",\"biases\":\"");
    first = 1;
    for (const Layer* l = network->firstlayer; l != NULL && ok; l = l->nextlayer) {
        for (const Neuron* n = l->firstneuron; n != NULL && ok; n = n->nextneuron) {
            ok = FlatAppend(buf, cap, &len, first ? "%.9g" : ",%.9g", (double)n->bias);
            first = 0;
        }
    }
    ok = ok && FlatAppend(buf, cap, &len, "\"}}");
    if (!ok) {
        free(buf);
        return NULL;
    }
    return buf;
}
```
